# ioam3358 register map
Registers are 32-bit, access not given, no defined reset value unless marked. A register's access mark holds for its fields unless they carry their own. Addresses are absolute; registers are grouped by the start of their names; [hi:lo] are bit positions; {n}, {i} and the like mark numbered series.

## DMTIMER5
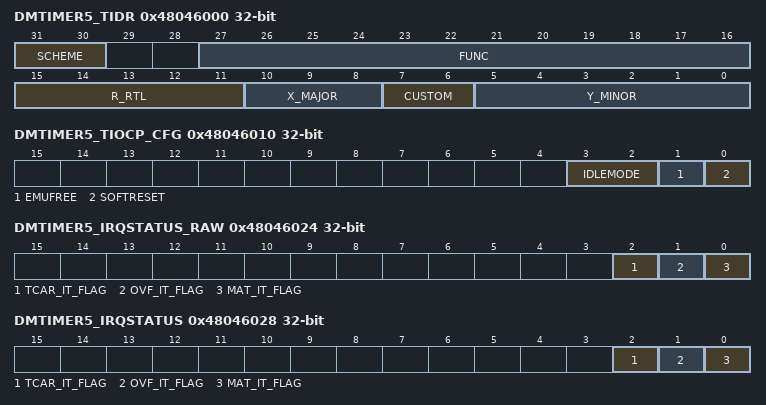
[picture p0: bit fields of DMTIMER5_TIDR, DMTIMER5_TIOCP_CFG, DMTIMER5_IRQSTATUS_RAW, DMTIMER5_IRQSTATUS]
0x48046000 DMTIMER5_TIDR
  [31:30] SCHEME, [27:16] FUNC, [15:11] R_RTL, [10:8] X_MAJOR, [7:6] CUSTOM, [5:0] Y_MINOR
0x48046010 DMTIMER5_TIOCP_CFG
  [3:2] IDLEMODE, [1] EMUFREE, [0] SOFTRESET
0x48046020 DMTIMER5_IRQ_EOI
  [0] LINE_NUMBER
0x48046024 DMTIMER5_IRQSTATUS_RAW
  [2] TCAR_IT_FLAG, [1] OVF_IT_FLAG, [0] MAT_IT_FLAG
0x48046028 DMTIMER5_IRQSTATUS
  [2] TCAR_IT_FLAG, [1] OVF_IT_FLAG, [0] MAT_IT_FLAG
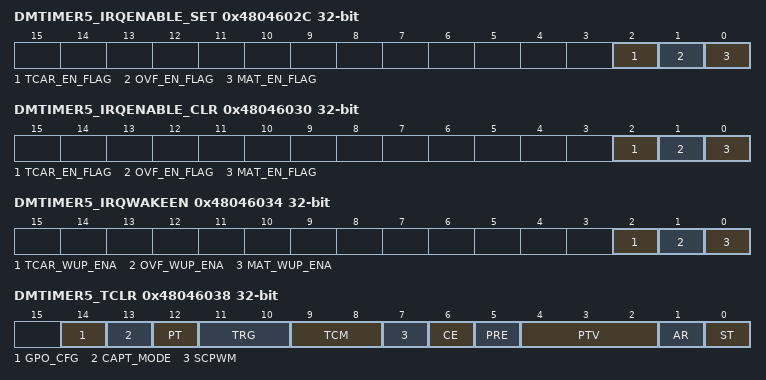
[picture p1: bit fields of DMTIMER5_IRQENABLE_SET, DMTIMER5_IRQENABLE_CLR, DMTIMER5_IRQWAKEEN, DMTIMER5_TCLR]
0x4804602C DMTIMER5_IRQENABLE_SET
  [2] TCAR_EN_FLAG, [1] OVF_EN_FLAG, [0] MAT_EN_FLAG
0x48046030 DMTIMER5_IRQENABLE_CLR
  [2] TCAR_EN_FLAG, [1] OVF_EN_FLAG, [0] MAT_EN_FLAG
0x48046034 DMTIMER5_IRQWAKEEN
  [2] TCAR_WUP_ENA, [1] OVF_WUP_ENA, [0] MAT_WUP_ENA
0x48046038 DMTIMER5_TCLR
  [14] GPO_CFG, [13] CAPT_MODE, [12] PT, [11:10] TRG, [9:8] TCM, [7] SCPWM, [6] CE, [5] PRE, [4:2] PTV, [1] AR, [0] ST
0x4804603C DMTIMER5_TCRR
0x48046040 DMTIMER5_TLDR
0x48046044 DMTIMER5_TTGR
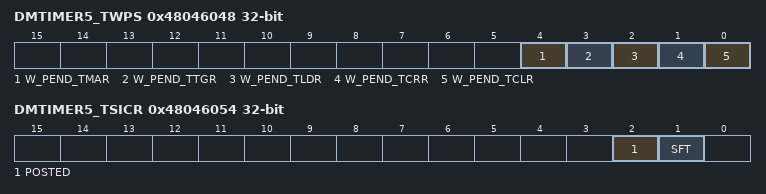
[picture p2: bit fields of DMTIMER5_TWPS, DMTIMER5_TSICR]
0x48046048 DMTIMER5_TWPS
  [4] W_PEND_TMAR, [3] W_PEND_TTGR, [2] W_PEND_TLDR, [1] W_PEND_TCRR, [0] W_PEND_TCLR
0x4804604C DMTIMER5_TMAR
0x48046050 DMTIMER5_TCAR1
0x48046054 DMTIMER5_TSICR
  [2] POSTED, [1] SFT
0x48046058 DMTIMER5_TCAR2

## DMTIMER6
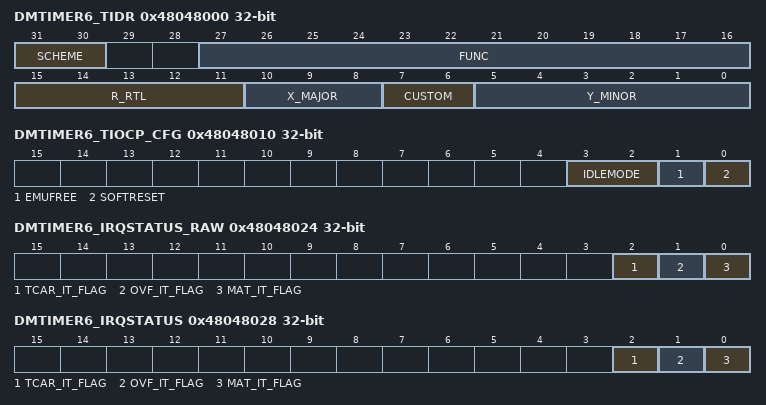
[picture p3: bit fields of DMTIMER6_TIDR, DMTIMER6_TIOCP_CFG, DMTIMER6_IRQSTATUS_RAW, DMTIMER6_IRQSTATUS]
0x48048000 DMTIMER6_TIDR
  [31:30] SCHEME, [27:16] FUNC, [15:11] R_RTL, [10:8] X_MAJOR, [7:6] CUSTOM, [5:0] Y_MINOR
0x48048010 DMTIMER6_TIOCP_CFG
  [3:2] IDLEMODE, [1] EMUFREE, [0] SOFTRESET
0x48048020 DMTIMER6_IRQ_EOI
  [0] LINE_NUMBER
0x48048024 DMTIMER6_IRQSTATUS_RAW
  [2] TCAR_IT_FLAG, [1] OVF_IT_FLAG, [0] MAT_IT_FLAG
0x48048028 DMTIMER6_IRQSTATUS
  [2] TCAR_IT_FLAG, [1] OVF_IT_FLAG, [0] MAT_IT_FLAG
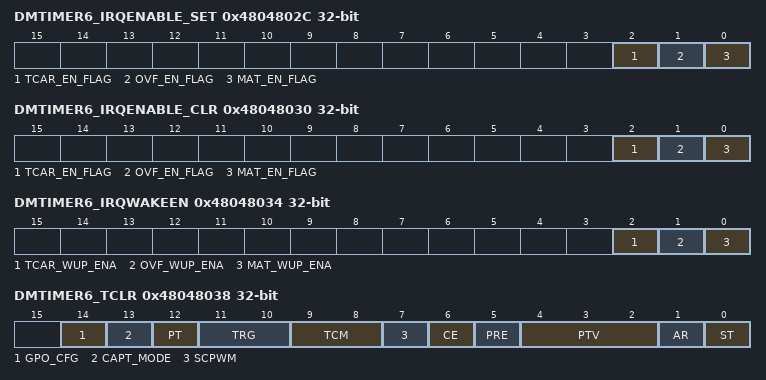
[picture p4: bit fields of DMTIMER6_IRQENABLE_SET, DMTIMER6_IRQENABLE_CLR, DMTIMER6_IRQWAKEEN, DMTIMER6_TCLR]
0x4804802C DMTIMER6_IRQENABLE_SET
  [2] TCAR_EN_FLAG, [1] OVF_EN_FLAG, [0] MAT_EN_FLAG
0x48048030 DMTIMER6_IRQENABLE_CLR
  [2] TCAR_EN_FLAG, [1] OVF_EN_FLAG, [0] MAT_EN_FLAG
0x48048034 DMTIMER6_IRQWAKEEN
  [2] TCAR_WUP_ENA, [1] OVF_WUP_ENA, [0] MAT_WUP_ENA
0x48048038 DMTIMER6_TCLR
  [14] GPO_CFG, [13] CAPT_MODE, [12] PT, [11:10] TRG, [9:8] TCM, [7] SCPWM, [6] CE, [5] PRE, [4:2] PTV, [1] AR, [0] ST
0x4804803C DMTIMER6_TCRR
0x48048040 DMTIMER6_TLDR
0x48048044 DMTIMER6_TTGR
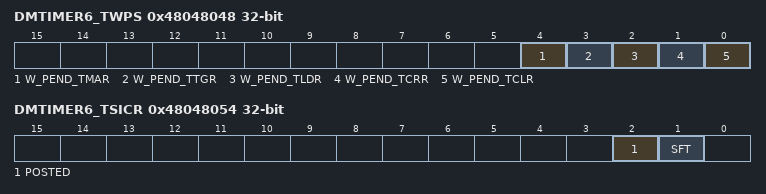
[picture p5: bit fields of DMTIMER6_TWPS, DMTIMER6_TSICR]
0x48048048 DMTIMER6_TWPS
  [4] W_PEND_TMAR, [3] W_PEND_TTGR, [2] W_PEND_TLDR, [1] W_PEND_TCRR, [0] W_PEND_TCLR
0x4804804C DMTIMER6_TMAR
0x48048050 DMTIMER6_TCAR1
0x48048054 DMTIMER6_TSICR
  [2] POSTED, [1] SFT
0x48048058 DMTIMER6_TCAR2

## DMTIMER7
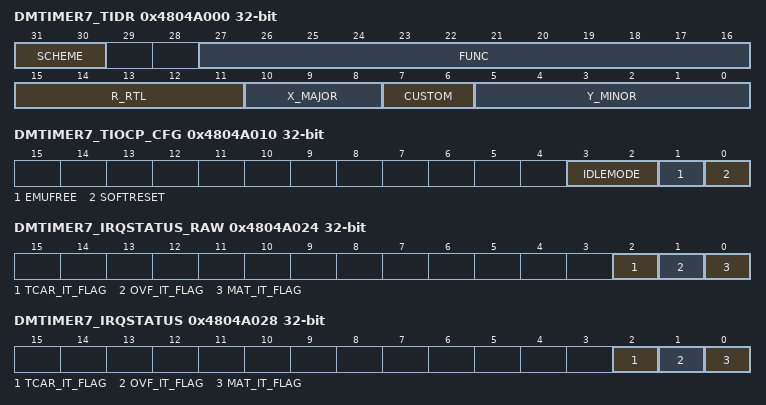
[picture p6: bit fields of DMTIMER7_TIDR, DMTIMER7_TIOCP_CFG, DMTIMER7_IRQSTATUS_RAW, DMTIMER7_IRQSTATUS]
0x4804A000 DMTIMER7_TIDR
  [31:30] SCHEME, [27:16] FUNC, [15:11] R_RTL, [10:8] X_MAJOR, [7:6] CUSTOM, [5:0] Y_MINOR
0x4804A010 DMTIMER7_TIOCP_CFG
  [3:2] IDLEMODE, [1] EMUFREE, [0] SOFTRESET
0x4804A020 DMTIMER7_IRQ_EOI
  [0] LINE_NUMBER
0x4804A024 DMTIMER7_IRQSTATUS_RAW
  [2] TCAR_IT_FLAG, [1] OVF_IT_FLAG, [0] MAT_IT_FLAG
0x4804A028 DMTIMER7_IRQSTATUS
  [2] TCAR_IT_FLAG, [1] OVF_IT_FLAG, [0] MAT_IT_FLAG
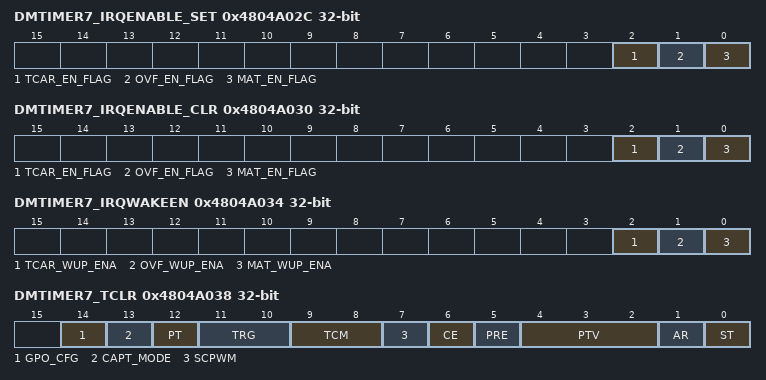
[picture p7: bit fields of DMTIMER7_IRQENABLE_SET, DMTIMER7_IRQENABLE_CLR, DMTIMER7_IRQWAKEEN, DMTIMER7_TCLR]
0x4804A02C DMTIMER7_IRQENABLE_SET
  [2] TCAR_EN_FLAG, [1] OVF_EN_FLAG, [0] MAT_EN_FLAG
0x4804A030 DMTIMER7_IRQENABLE_CLR
  [2] TCAR_EN_FLAG, [1] OVF_EN_FLAG, [0] MAT_EN_FLAG
0x4804A034 DMTIMER7_IRQWAKEEN
  [2] TCAR_WUP_ENA, [1] OVF_WUP_ENA, [0] MAT_WUP_ENA
0x4804A038 DMTIMER7_TCLR
  [14] GPO_CFG, [13] CAPT_MODE, [12] PT, [11:10] TRG, [9:8] TCM, [7] SCPWM, [6] CE, [5] PRE, [4:2] PTV, [1] AR, [0] ST
0x4804A03C DMTIMER7_TCRR
0x4804A040 DMTIMER7_TLDR
0x4804A044 DMTIMER7_TTGR
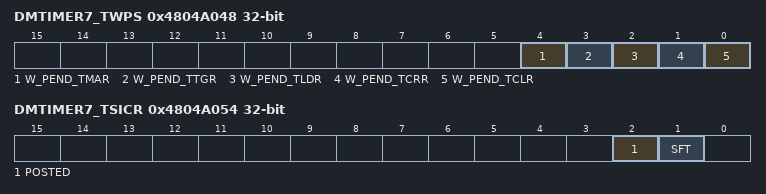
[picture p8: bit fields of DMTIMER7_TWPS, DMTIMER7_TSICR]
0x4804A048 DMTIMER7_TWPS
  [4] W_PEND_TMAR, [3] W_PEND_TTGR, [2] W_PEND_TLDR, [1] W_PEND_TCRR, [0] W_PEND_TCLR
0x4804A04C DMTIMER7_TMAR
0x4804A050 DMTIMER7_TCAR1
0x4804A054 DMTIMER7_TSICR
  [2] POSTED, [1] SFT
0x4804A058 DMTIMER7_TCAR2

## RTC
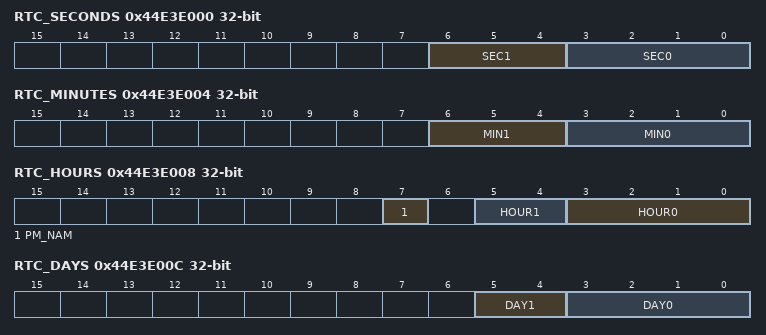
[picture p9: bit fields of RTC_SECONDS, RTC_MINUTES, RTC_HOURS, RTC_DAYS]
0x44E3E000 RTC_SECONDS
  [6:4] SEC1, [3:0] SEC0
0x44E3E004 RTC_MINUTES
  [6:4] MIN1, [3:0] MIN0
0x44E3E008 RTC_HOURS
  [7] PM_NAM, [5:4] HOUR1, [3:0] HOUR0
0x44E3E00C RTC_DAYS
  [5:4] DAY1, [3:0] DAY0
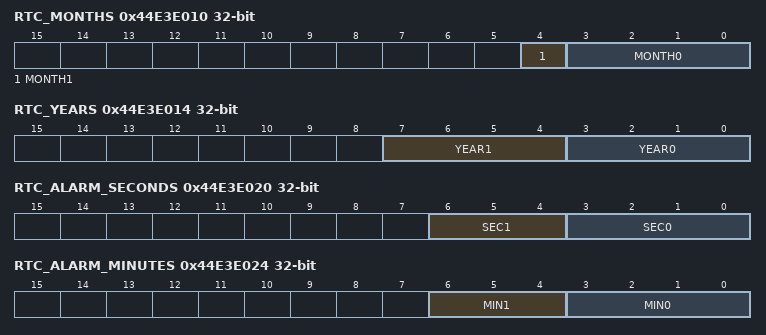
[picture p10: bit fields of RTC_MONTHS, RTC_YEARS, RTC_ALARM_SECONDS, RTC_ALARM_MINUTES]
0x44E3E010 RTC_MONTHS
  [4] MONTH1, [3:0] MONTH0
0x44E3E014 RTC_YEARS
  [7:4] YEAR1, [3:0] YEAR0
0x44E3E018 RTC_WEEK
  [2:0] WEEK
0x44E3E020 RTC_ALARM_SECONDS
  [6:4] SEC1, [3:0] SEC0
0x44E3E024 RTC_ALARM_MINUTES
  [6:4] MIN1, [3:0] MIN0
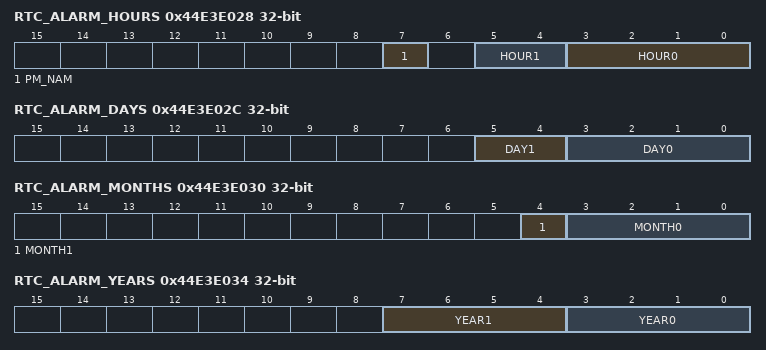
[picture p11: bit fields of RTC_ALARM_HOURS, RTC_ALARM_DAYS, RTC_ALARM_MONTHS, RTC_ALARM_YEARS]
0x44E3E028 RTC_ALARM_HOURS
  [7] PM_NAM, [5:4] HOUR1, [3:0] HOUR0
0x44E3E02C RTC_ALARM_DAYS
  [5:4] DAY1, [3:0] DAY0
0x44E3E030 RTC_ALARM_MONTHS
  [4] MONTH1, [3:0] MONTH0
0x44E3E034 RTC_ALARM_YEARS
  [7:4] YEAR1, [3:0] YEAR0
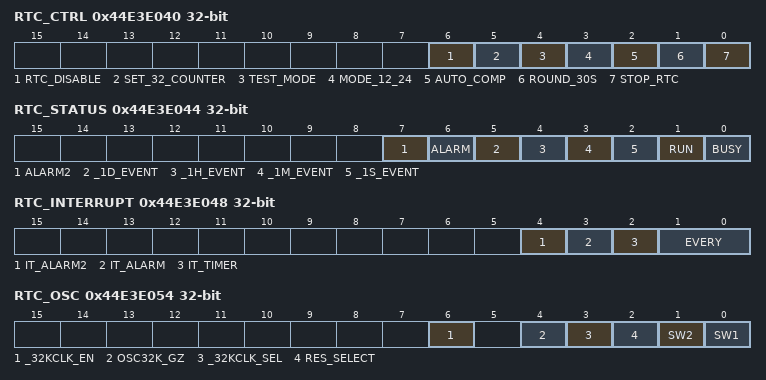
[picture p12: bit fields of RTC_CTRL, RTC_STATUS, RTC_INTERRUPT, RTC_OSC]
0x44E3E040 RTC_CTRL
  [6] RTC_DISABLE, [5] SET_32_COUNTER, [4] TEST_MODE, [3] MODE_12_24, [2] AUTO_COMP, [1] ROUND_30S, [0] STOP_RTC
0x44E3E044 RTC_STATUS
  [7] ALARM2, [6] ALARM, [5] _1D_EVENT, [4] _1H_EVENT, [3] _1M_EVENT, [2] _1S_EVENT, [1] RUN, [0] BUSY
0x44E3E048 RTC_INTERRUPT
  [4] IT_ALARM2, [3] IT_ALARM, [2] IT_TIMER, [1:0] EVERY
0x44E3E04C RTC_COMP_LSB
  [7:0] RTC_COMP_LSB
0x44E3E050 RTC_COMP_MSB
  [7:0] RTC_COMP_MSB
0x44E3E054 RTC_OSC
  [6] _32KCLK_EN, [4] OSC32K_GZ, [3] _32KCLK_SEL, [2] RES_SELECT, [1] SW2, [0] SW1
{0x44E3E060+4i} RTC_SCRATCH{i} (i=0..2)
0x44E3E06C RTC_KICK0
0x44E3E070 RTC_KICK1
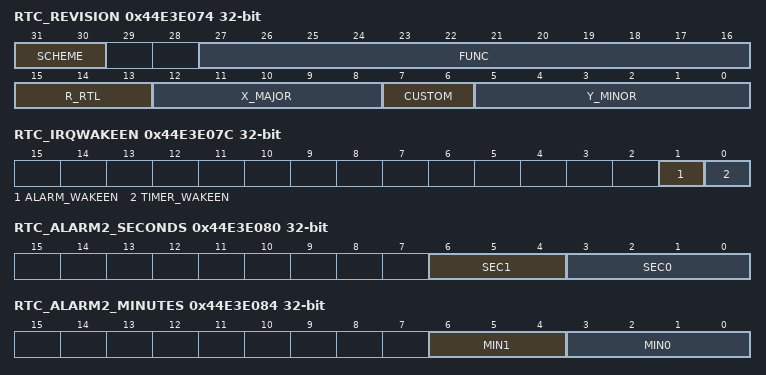
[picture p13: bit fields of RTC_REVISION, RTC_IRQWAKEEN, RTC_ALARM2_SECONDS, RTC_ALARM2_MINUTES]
0x44E3E074 RTC_REVISION
  [31:30] SCHEME, [27:16] FUNC, [15:13] R_RTL, [12:8] X_MAJOR, [7:6] CUSTOM, [5:0] Y_MINOR
0x44E3E078 RTC_SYSCONFIG
  [1:0] IDLEMODE
0x44E3E07C RTC_IRQWAKEEN
  [1] ALARM_WAKEEN, [0] TIMER_WAKEEN
0x44E3E080 RTC_ALARM2_SECONDS
  [6:4] SEC1, [3:0] SEC0
0x44E3E084 RTC_ALARM2_MINUTES
  [6:4] MIN1, [3:0] MIN0
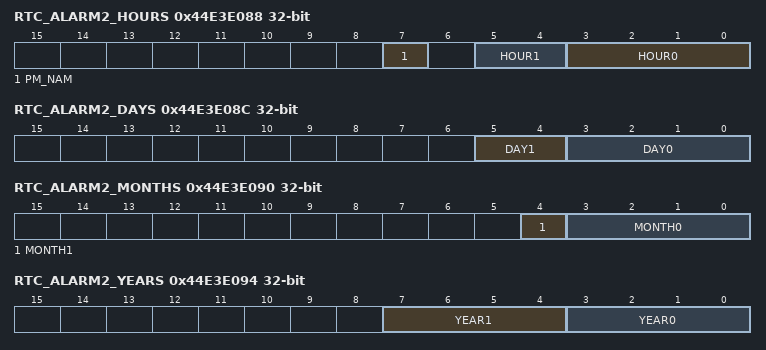
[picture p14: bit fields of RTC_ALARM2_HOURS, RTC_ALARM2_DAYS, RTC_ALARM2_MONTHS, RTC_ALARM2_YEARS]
0x44E3E088 RTC_ALARM2_HOURS
  [7] PM_NAM, [5:4] HOUR1, [3:0] HOUR0
0x44E3E08C RTC_ALARM2_DAYS
  [5:4] DAY1, [3:0] DAY0
0x44E3E090 RTC_ALARM2_MONTHS
  [4] MONTH1, [3:0] MONTH0
0x44E3E094 RTC_ALARM2_YEARS
  [7:4] YEAR1, [3:0] YEAR0
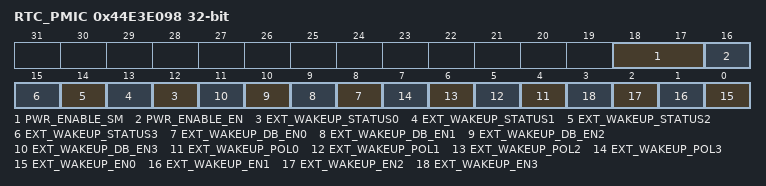
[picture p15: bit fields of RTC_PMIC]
0x44E3E098 RTC_PMIC
  [18:17] PWR_ENABLE_SM, [16] PWR_ENABLE_EN, [n+12] EXT_WAKEUP_STATUS{n} (n=0..3), [n+8] EXT_WAKEUP_DB_EN{n} (n=0..3), [n+4] EXT_WAKEUP_POL{n} (n=0..3), [n] EXT_WAKEUP_EN{n} (n=0..3)
0x44E3E09C RTC_DEBOUNCE
  [7:0] DEBOUNCE_REG
